# CPSW0_NUSS_PCSR register map
Vendor: Texas Instruments
Peripheral module from a debugger description file (folder J7VCL).
Registers are 32-bit, read-write, reset 0x0 unless marked. A register's access mark holds for its fields unless they carry their own. Offsets are as the file gives them; lines under a group give offsets from that group; [hi:lo] are bit positions; {n}, {i} and the like mark numbered series; 'fields as' and 'values as' point back to an identical list; <NAME> marks a mode.

## CPSW0_NUSS_PCSR
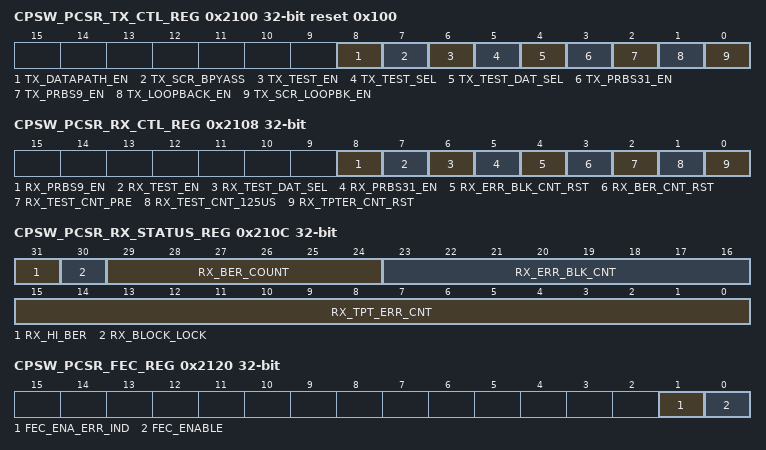
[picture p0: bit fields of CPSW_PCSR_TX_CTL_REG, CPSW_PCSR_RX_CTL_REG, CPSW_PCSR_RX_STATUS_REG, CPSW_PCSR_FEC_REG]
0x2100 CPSW_PCSR_TX_CTL_REG reset 0x100 — PCSR Transmit Control Register.
  [8] TX_DATAPATH_EN — PCSR Transmit Datapath Enable.
  [7] TX_SCR_BPYASS — PCSR Transmit SCR Bypass.
  [6] TX_TEST_EN — PCSR Transmit Test Enable.
  [5] TX_TEST_SEL — PCSR Transmit Test Select.
  [4] TX_TEST_DAT_SEL — PCSR Transmit Test Data Select.
  [3] TX_PRBS31_EN — PCSR Transmit PRBS31 Enable.
  [2] TX_PRBS9_EN — PCSR Transmit PRBS9 Enable.
  [1] TX_LOOPBACK_EN — PCSR Transmit Loopback Enable.
  [0] TX_SCR_LOOPBK_EN — PCSR Transmit SCR Loopback Enable.
0x2104 CPSW_PCSR_TX_STATUS_REG — PCSR Transmit Status Register.
  [8] TX_FAULT — PCSR Transmit Fault Hold Register - write 1 to clear.
0x2108 CPSW_PCSR_RX_CTL_REG — PCSR Receive Control Register.
  [8] RX_PRBS9_EN — PCSR Receive PRBS9 Enable.
  [7] RX_TEST_EN — PCSR Receive Test Enable.
  [6] RX_TEST_DAT_SEL — PCSR Receive Test Data Select.
  [5] RX_PRBS31_EN — PCSR Receive PRBS31 Enable.
  [4] RX_ERR_BLK_CNT_RST — PCSR Receive Error Block Count Reset.
  [3] RX_BER_CNT_RST — PCSR Receive BER Count Reset.
  [2] RX_TEST_CNT_PRE — PCSR Receive Test Count Pre.
  [1] RX_TEST_CNT_125US — PCSR Receive Test Count 125us.
  [0] RX_TPTER_CNT_RST — PCSR Receive TPTER Count Reset
0x210C CPSW_PCSR_RX_STATUS_REG ro — PCSR Receive Status Register.
  [31] RX_HI_BER — PCSR Receive High BER.
  [30] RX_BLOCK_LOCK — PCSR Receive Block Lock.
  [29:24] RX_BER_COUNT — PCSR Receive BER Count.
  [23:16] RX_ERR_BLK_CNT — PCSR Error Block Count.
  [15:0] RX_TPT_ERR_CNT — PCSR TPT Error Count.
0x2110 CPSW_PCSR_SEED_A_LO_REG — PCSR Seed A Low Register.
  [31:0] SEED_A_LO — PCSR Seed A Low.
0x2114 CPSW_PCSR_SEED_A_HI_REG — PCSR Seed A High Register.
  [25:0] SEED_A_HI — PCSR Seed A High.
0x2118 CPSW_PCSR_SEED_B_LO_REG — PCSR Seed B Low Register.
  [31:0] SEED_B_LO — PCSR Seed B Low.
0x211C CPSW_PCSR_SEED_B_HI_REG — PCSR Seed B High Register.
  [25:0] SEED_B_HI — PCSR Seed B High.
0x2120 CPSW_PCSR_FEC_REG — PCSR FEC Register.
  [1] FEC_ENA_ERR_IND — PCSR FEC ENA Error Ind.
  [0] FEC_ENABLE — PCSR FEC Enable.
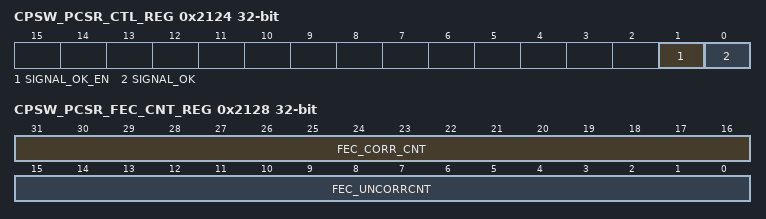
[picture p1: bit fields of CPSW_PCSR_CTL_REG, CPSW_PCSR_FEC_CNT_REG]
0x2124 CPSW_PCSR_CTL_REG — PCSR Control Register.
  [1] SIGNAL_OK_EN — PCSR Signal OK Enable.
  [0] SIGNAL_OK — PCSR Signal OK.
0x2128 CPSW_PCSR_FEC_CNT_REG — PCSR FEC Count Register.
  [31:16] FEC_CORR_CNT — PCSR FEC Corrected Error Count.
  [15:0] FEC_UNCORRCNT — PCSR FEC Uncorrected Error Count.
0x212C CPSW_PCSR_ERROR_FIFO_REG — PCSR Error FIFO Register.
  [0] ERROR_FIFO_CTC — PCSR Error FIFO CTC.
